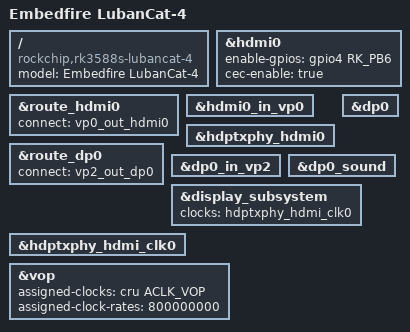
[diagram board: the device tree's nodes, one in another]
// SPDX-License-Identifier: (GPL-2.0+ OR MIT)
/*
 * Copyright (c) 2021 Rockchip Electronics Co., Ltd.
 * Copyright (c) 2023 EmbedFire <embedfire@embedfire.com>
 */
/dts-v1/;

#include "rk3588s-lubancat-4.dtsi"
#include "rk3588-android.dtsi"

/ {
	model = "Embedfire LubanCat-4";
	compatible = "rockchip,rk3588s-lubancat-4", "rockchip,rk3588";
};

/* hdmi0 display */

&hdmi0 {
	enable-gpios = <&gpio4 RK_PB6 GPIO_ACTIVE_HIGH>;
	cec-enable = "true";
	status = "okay";
};

&route_hdmi0{
	status = "okay";
	connect = <&vp0_out_hdmi0>;
};

&hdmi0_in_vp0 {
	status = "okay";
};

&hdptxphy_hdmi0 {
	status = "okay";
};

/* dp0 display */

&dp0 {
	status = "okay";
};

&route_dp0 {
	status = "okay";
	connect = <&vp2_out_dp0>;	
};

&dp0_in_vp2 {
	status = "okay";
};

&dp0_sound{
	status = "okay";
};

&display_subsystem {
	clocks = <&hdptxphy_hdmi_clk0>;
	clock-names = "hdmi0_phy_pll";
};

&hdptxphy_hdmi_clk0 {
    status = "okay";
};

&vop {
	status = "okay";
	assigned-clocks = <&cru ACLK_VOP>;
	assigned-clock-rates = <800000000>;
};
